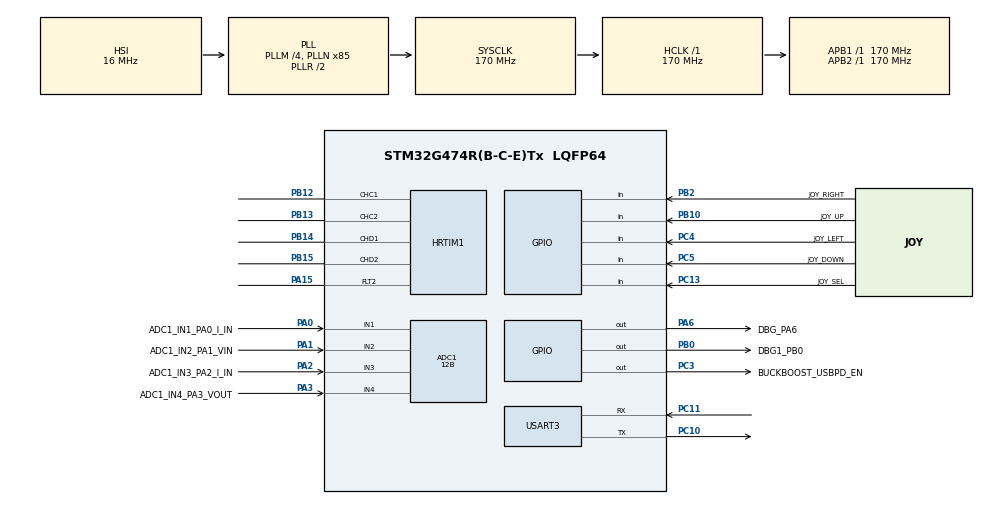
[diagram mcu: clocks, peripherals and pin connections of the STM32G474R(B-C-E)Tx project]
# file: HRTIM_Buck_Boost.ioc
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ADC1.Channel-5\#ChannelRegularConversion=ADC_CHANNEL_2
ADC1.ClockPrescaler=ADC_CLOCK_SYNC_PCLK_DIV4
ADC1.ContinuousConvMode=DISABLE
ADC1.DMAContinuousRequests=DISABLE
ADC1.DataAlign=ADC_DATAALIGN_RIGHT
ADC1.DiscontinuousConvMode=DISABLE
ADC1.EOCSelection=ADC_EOC_SINGLE_CONV
ADC1.EnableAnalogWatchDog1=false
ADC1.EnableAnalogWatchDog2=false
ADC1.EnableAnalogWatchDog3=false
ADC1.EnableInjectedConversion=ENABLE
ADC1.EnableInjectedOversampling=DISABLE
ADC1.EnableRegularConversion=ENABLE
ADC1.ExternalTrigConv=ADC_SOFTWARE_START
ADC1.ExternalTrigConvEdge=ADC_EXTERNALTRIGCONVEDGE_NONE
ADC1.ExternalTrigInjecConv=ADC_EXTERNALTRIGINJEC_HRTIM_TRG2
ADC1.ExternalTrigInjecConvEdge=ADC_EXTERNALTRIGINJECCONV_EDGE_RISING
ADC1.GainCompensation=0
ADC1.InjNumberOfConversion=4
ADC1.InjectedChannel-2\#ChannelInjectedConversion=ADC_CHANNEL_1
ADC1.InjectedChannel-4\#ChannelInjectedConversion=ADC_CHANNEL_2
ADC1.InjectedChannel-6\#ChannelInjectedConversion=ADC_CHANNEL_3
ADC1.InjectedChannel-7\#ChannelInjectedConversion=ADC_CHANNEL_4
ADC1.InjectedConvMode=None
ADC1.InjectedOffsetNumber-2\#ChannelInjectedConversion=ADC_OFFSET_NONE
ADC1.InjectedOffsetNumber-4\#ChannelInjectedConversion=ADC_OFFSET_NONE
ADC1.InjectedOffsetNumber-6\#ChannelInjectedConversion=ADC_OFFSET_NONE
ADC1.InjectedOffsetNumber-7\#ChannelInjectedConversion=ADC_OFFSET_NONE
ADC1.InjectedRank-2\#ChannelInjectedConversion=1
ADC1.InjectedRank-4\#ChannelInjectedConversion=2
ADC1.InjectedRank-6\#ChannelInjectedConversion=3
ADC1.InjectedRank-7\#ChannelInjectedConversion=4
ADC1.InjectedSamplingTime-2\#ChannelInjectedConversion=ADC_SAMPLETIME_247CYCLES_5
ADC1.InjectedSamplingTime-4\#ChannelInjectedConversion=ADC_SAMPLETIME_247CYCLES_5
ADC1.InjectedSamplingTime-6\#ChannelInjectedConversion=ADC_SAMPLETIME_247CYCLES_5
ADC1.InjectedSamplingTime-7\#ChannelInjectedConversion=ADC_SAMPLETIME_247CYCLES_5
ADC1.LowPowerAutoWait=DISABLE
ADC1.Mode=ADC_MODE_INDEPENDENT
ADC1.NbrOfConversion=1
ADC1.OffsetNumber-5\#ChannelRegularConversion=ADC_OFFSET_NONE
ADC1.Overrun=ADC_OVR_DATA_PRESERVED
ADC1.OversamplingMode=DISABLE
ADC1.Rank-5\#ChannelRegularConversion=1
ADC1.Rank1_Channel=ADC_CHANNEL_1
ADC1.Rank2_Channel=ADC_CHANNEL_2
ADC1.Rank3_Channel=ADC_CHANNEL_3
ADC1.Rank4_Channel=ADC_CHANNEL_4
ADC1.Resolution=ADC_RESOLUTION_12B
ADC1.SamplingTime-5\#ChannelRegularConversion=ADC_SAMPLETIME_247CYCLES_5
ADC1.ScanConvMode=ADC_SCAN_ENABLE
ADC1.injectedQueueMode=DISABLE
ADC1.master=1
HRTIM1.ADCTrigger2_Source1=HRTIM_ADCTRIGGEREVENT24_TIMERC_CMP2
HRTIM1.ADCTrigger_Id1=__NULL
HRTIM1.ADCTrigger_Id10=__NULL
HRTIM1.ADCTrigger_Id2=HRTIM_ADCTRIGGER_2
HRTIM1.ADCTrigger_Id3=__NULL
HRTIM1.ADCTrigger_Id4=__NULL
HRTIM1.ADCTrigger_Id5=__NULL
HRTIM1.ADCTrigger_Id6=__NULL
HRTIM1.ADCTrigger_Id7=__NULL
HRTIM1.ADCTrigger_Id8=__NULL
HRTIM1.ADCTrigger_Id9=__NULL
HRTIM1.AutoDelayedMode2-Output_TC1TC2=HRTIM_AUTODELAYEDMODE_REGULAR
HRTIM1.BlankingSourceFaultLine2=HRTIM_FAULTBLANKINGMODE_RSTALIGNED
HRTIM1.BurstDMAconfig-Output_TC1TC2=__NULL
HRTIM1.BurstDMAconfig-Output_TD1TD2=__NULL
HRTIM1.BurstMode-Output_TC1TC2=HRTIM_TIMERBURSTMODE_MAINTAINCLOCK
HRTIM1.BurstMode-Output_TD1TD2=HRTIM_TIMERBURSTMODE_MAINTAINCLOCK
HRTIM1.BurstModeEntryDelayed1-Output_TC1TC2=HRTIM_OUTPUTBURSTMODEENTRY_REGULAR
HRTIM1.BurstModeEntryDelayed1-Output_TD1TD2=HRTIM_OUTPUTBURSTMODEENTRY_REGULAR
HRTIM1.BurstModeEntryDelayed2-Output_TC1TC2=HRTIM_OUTPUTBURSTMODEENTRY_REGULAR
HRTIM1.BurstModeEntryDelayed2-Output_TD1TD2=HRTIM_OUTPUTBURSTMODEENTRY_REGULAR
HRTIM1.CaptureUnit1-Output_TC1TC2=__NULL
HRTIM1.CaptureUnit1-Output_TD1TD2=__NULL
HRTIM1.CaptureUnit2-Output_TC1TC2=__NULL
HRTIM1.CaptureUnit2-Output_TD1TD2=__NULL
HRTIM1.ChopperModeEnable1-Output_TC1TC2=HRTIM_OUTPUTCHOPPERMODE_DISABLED
HRTIM1.ChopperModeEnable1-Output_TD1TD2=HRTIM_OUTPUTCHOPPERMODE_DISABLED
HRTIM1.ChopperModeEnable2-Output_TC1TC2=HRTIM_OUTPUTCHOPPERMODE_DISABLED
HRTIM1.ChopperModeEnable2-Output_TD1TD2=HRTIM_OUTPUTCHOPPERMODE_DISABLED
HRTIM1.ChopperModeconfig-Output_TC1TC2=__NULL
HRTIM1.ChopperModeconfig-Output_TD1TD2=__NULL
HRTIM1.CompareUnit1-Output_TC1TC2=HRTIM_COMPAREUNIT_1
HRTIM1.CompareUnit1-Output_TD1TD2=HRTIM_COMPAREUNIT_1
HRTIM1.CompareUnit2-Output_TC1TC2=HRTIM_COMPAREUNIT_2
HRTIM1.CompareUnit2-Output_TD1TD2=__NULL
HRTIM1.CompareUnit3-Output_TC1TC2=__NULL
HRTIM1.CompareUnit3-Output_TD1TD2=__NULL
HRTIM1.CompareUnit4-Output_TC1TC2=__NULL
HRTIM1.CompareUnit4-Output_TD1TD2=__NULL
HRTIM1.CompareValue1-Output_TC1TC2=BUCK_PWM_PERIOD - 0x60
HRTIM1.CompareValue1-Output_TD1TD2=BUCK_PWM_PERIOD+1
HRTIM1.CompareValue2-Output_TC1TC2=BUCK_PWM_PERIOD/2
HRTIM1.Configuration_TC=Waveform
HRTIM1.Configuration_TD=Waveform
HRTIM1.CounterFaultLine2=0
HRTIM1.DACSynchro-Output_TC1TC2=HRTIM_DACSYNC_NONE
HRTIM1.DACSynchro-Output_TD1TD2=HRTIM_DACSYNC_NONE
HRTIM1.DeadTimeInsertion-Output_TC1TC2=HRTIM_TIMDEADTIMEINSERTION_ENABLED
HRTIM1.DeadTimeInsertion-Output_TD1TD2=HRTIM_TIMDEADTIMEINSERTION_ENABLED
HRTIM1.Deadtimeconfig-Output_TC1TC2=HRTIM_TIMERINDEX_TIMER_C
HRTIM1.Deadtimeconfig-Output_TD1TD2=HRTIM_TIMERINDEX_TIMER_D
HRTIM1.DelayedProtectionMode-Output_TC1TC2=HRTIM_TIMER_A_B_C_DELAYEDPROTECTION_DISABLED
HRTIM1.DelayedProtectionMode-Output_TD1TD2=HRTIM_TIMER_D_E_DELAYEDPROTECTION_DISABLED
HRTIM1.DualChannelDacEnableFake_TC-Output_TC1TC2=HRTIM_TIMER_DCDE_DISABLED
HRTIM1.DualChannelDacEnableFake_TD-Output_TD1TD2=HRTIM_TIMER_DCDE_DISABLED
HRTIM1.Enable=HRTIM_BURSTMODECTL_DISABLED
HRTIM1.Enable_FaultLine2=HRTIM_FAULTMODECTL_ENABLED
HRTIM1.Event1-Output_TC1TC2=__NULL
HRTIM1.Event1-Output_TD1TD2=__NULL
HRTIM1.Event10-Output_TC1TC2=__NULL
HRTIM1.Event10-Output_TD1TD2=__NULL
HRTIM1.Event2-Output_TC1TC2=__NULL
HRTIM1.Event2-Output_TD1TD2=__NULL
HRTIM1.Event3-Output_TC1TC2=__NULL
HRTIM1.Event3-Output_TD1TD2=__NULL
HRTIM1.Event4-Output_TC1TC2=__NULL
HRTIM1.Event4-Output_TD1TD2=__NULL
HRTIM1.Event5-Output_TC1TC2=__NULL
HRTIM1.Event5-Output_TD1TD2=__NULL
HRTIM1.Event6-Output_TC1TC2=__NULL
HRTIM1.Event6-Output_TD1TD2=__NULL
HRTIM1.Event7-Output_TC1TC2=__NULL
HRTIM1.Event7-Output_TD1TD2=__NULL
HRTIM1.Event8-Output_TC1TC2=__NULL
HRTIM1.Event8-Output_TD1TD2=__NULL
HRTIM1.Event9-Output_TC1TC2=__NULL
HRTIM1.Event9-Output_TD1TD2=__NULL
HRTIM1.EventEnableA-Output_TC1TC2=__NULL
HRTIM1.EventEnableA-Output_TD1TD2=__NULL
HRTIM1.Event_EEV1=__NULL
HRTIM1.Event_EEV10=__NULL
HRTIM1.Event_EEV2=__NULL
HRTIM1.Event_EEV3=__NULL
HRTIM1.Event_EEV4=__NULL
HRTIM1.Event_EEV5=__NULL
HRTIM1.Event_EEV6=__NULL
HRTIM1.Event_EEV7=__NULL
HRTIM1.Event_EEV8=__NULL
HRTIM1.Event_EEV9=__NULL
HRTIM1.FallingLock-Output_TC1TC2=HRTIM_TIMDEADTIME_FALLINGLOCK_WRITE
HRTIM1.FallingLock-Output_TD1TD2=HRTIM_TIMDEADTIME_FALLINGLOCK_WRITE
HRTIM1.FallingSign-Output_TC1TC2=HRTIM_TIMDEADTIME_FALLINGSIGN_POSITIVE
HRTIM1.FallingSign-Output_TD1TD2=HRTIM_TIMDEADTIME_FALLINGSIGN_POSITIVE
HRTIM1.FallingSignLock-Output_TC1TC2=HRTIM_TIMDEADTIME_FALLINGSIGNLOCK_READONLY
HRTIM1.FallingSignLock-Output_TD1TD2=HRTIM_TIMDEADTIME_FALLINGSIGNLOCK_READONLY
HRTIM1.FallingValue-Output_TC1TC2=DT_FALLING
HRTIM1.FallingValue-Output_TD1TD2=DT_FALLING
HRTIM1.FaultEnable_Source1-Output_TC1TC2=HRTIM_TIMFAULTENABLE_FAULT2
HRTIM1.FaultEnable_Source1-Output_TD1TD2=HRTIM_TIMFAULTENABLE_FAULT2
HRTIM1.FaultLevel1-Output_TC1TC2=HRTIM_OUTPUTFAULTLEVEL_INACTIVE
HRTIM1.FaultLevel1-Output_TD1TD2=HRTIM_OUTPUTFAULTLEVEL_INACTIVE
HRTIM1.FaultLevel2-Output_TC1TC2=HRTIM_OUTPUTFAULTLEVEL_INACTIVE
HRTIM1.FaultLevel2-Output_TD1TD2=HRTIM_OUTPUTFAULTLEVEL_INACTIVE
HRTIM1.FaultLock-Output_TC1TC2=HRTIM_TIMFAULTLOCK_READWRITE
HRTIM1.FaultLock-Output_TD1TD2=HRTIM_TIMFAULTLOCK_READWRITE
HRTIM1.Fault_Line1=__NULL
HRTIM1.Fault_Line2=HRTIM_FAULT_2
HRTIM1.Fault_Line3=__NULL
HRTIM1.Fault_Line4=__NULL
HRTIM1.Fault_Line5=__NULL
HRTIM1.Fault_Line6=__NULL
HRTIM1.Filter_FaultLine2=HRTIM_FAULTFILTER_NONE
HRTIM1.GreaterCMP1_TC=HRTIM_TIMERGTCMP1_EQUAL
HRTIM1.GreaterCMP1_TD=HRTIM_TIMERGTCMP1_EQUAL
HRTIM1.HRTIMInterruptResquests1=HRTIM_IT_NONE
HRTIM1.HRTIMInterruptResquests2=HRTIM_IT_NONE
HRTIM1.HRTIMInterruptResquests3=HRTIM_IT_NONE
HRTIM1.HRTIMInterruptResquests4=HRTIM_IT_NONE
HRTIM1.HRTIMInterruptResquests5=HRTIM_IT_NONE
HRTIM1.HRTIMInterruptResquests6=HRTIM_IT_NONE
HRTIM1.HRTIMInterruptResquests7=HRTIM_IT_NONE
HRTIM1.HRTIMInterruptResquests8=HRTIM_IT_NONE
HRTIM1.HRTIMInterruptResquests9=HRTIM_IT_NONE
HRTIM1.IdleLevel1-Output_TC1TC2=HRTIM_OUTPUTIDLELEVEL_INACTIVE
HRTIM1.IdleLevel1-Output_TD1TD2=HRTIM_OUTPUTIDLELEVEL_INACTIVE
HRTIM1.IdleLevel2-Output_TC1TC2=HRTIM_OUTPUTIDLELEVEL_INACTIVE
HRTIM1.IdleLevel2-Output_TD1TD2=HRTIM_OUTPUTIDLELEVEL_INACTIVE
HRTIM1.IdleMode1-Output_TC1TC2=HRTIM_OUTPUTIDLEMODE_NONE
HRTIM1.IdleMode1-Output_TD1TD2=HRTIM_OUTPUTIDLEMODE_NONE
HRTIM1.IdleMode2-Output_TC1TC2=HRTIM_OUTPUTIDLEMODE_NONE
HRTIM1.IdleMode2-Output_TD1TD2=HRTIM_OUTPUTIDLEMODE_NONE
HRTIM1.InterleavedMode-Output_TC1TC2=HRTIM_INTERLEAVED_MODE_DISABLED
HRTIM1.InterleavedMode-Output_TD1TD2=HRTIM_INTERLEAVED_MODE_DISABLED
HRTIM1.InterruptRequests1-Output_TC1TC2=HRTIM_TIM_IT_REP
HRTIM1.InterruptRequests1-Output_TD1TD2=HRTIM_TIM_IT_REP
HRTIM1.Lock_FaultLine2=HRTIM_FAULTLOCK_READWRITE
HRTIM1.ModeTimeBase-Output_TC1TC2=HRTIM_MODE_CONTINUOUS
HRTIM1.ModeTimeBase-Output_TD1TD2=HRTIM_MODE_CONTINUOUS
HRTIM1.NumberADCTriggerSource2=1
HRTIM1.NumberDMARequests_TC=0
HRTIM1.NumberDMARequests_TD=0
HRTIM1.NumberFaultEnable-Output_TC1TC2=1
HRTIM1.NumberFaultEnable-Output_TD1TD2=1
HRTIM1.NumberInterruptRequests-Output_TC1TC2=1
HRTIM1.NumberInterruptRequests-Output_TD1TD2=1
HRTIM1.NumberResetSource1-Output_TC1TC2=1
HRTIM1.NumberResetSource1-Output_TD1TD2=1
HRTIM1.NumberResetSource2_TC=1
HRTIM1.NumberResetSource2_TD=1
HRTIM1.NumberResetTrigger-Output_TC1TC2=0
HRTIM1.NumberResetTrigger-Output_TD1TD2=0
HRTIM1.NumberSetSource1-Output_TC1TC2=1
HRTIM1.NumberSetSource1-Output_TD1TD2=1
HRTIM1.NumberSetSource2_TC=1
HRTIM1.NumberSetSource2_TD=1
HRTIM1.NumberUpdateTrigger-Output_TC1TC2=0
HRTIM1.NumberUpdateTrigger-Output_TD1TD2=0
HRTIM1.ORingUpdateSource_ADCTrigger2=HRTIM_ADCTRIGGERUPDATE_TIMER_C
HRTIM1.Output1-Output_TC1TC2=HRTIM_OUTPUT_TC1
HRTIM1.Output1-Output_TD1TD2=HRTIM_OUTPUT_TD1
HRTIM1.Output2-Output_TC1TC2=HRTIM_OUTPUT_TC2
HRTIM1.Output2-Output_TD1TD2=HRTIM_OUTPUT_TD2
HRTIM1.Periode_TC=BUCK_PWM_PERIOD
HRTIM1.Periode_TD=BUCK_PWM_PERIOD
HRTIM1.Polarity1-Output_TC1TC2=HRTIM_OUTPUTPOLARITY_HIGH
HRTIM1.Polarity1-Output_TD1TD2=HRTIM_OUTPUTPOLARITY_HIGH
HRTIM1.Polarity2-Output_TC1TC2=HRTIM_OUTPUTPOLARITY_HIGH
HRTIM1.Polarity2-Output_TD1TD2=HRTIM_OUTPUTPOLARITY_HIGH
HRTIM1.Polarity_FaultLine2=HRTIM_FAULTPOLARITY_LOW
HRTIM1.PreloadEnable-Output_TC1TC2=HRTIM_PRELOAD_ENABLED
HRTIM1.PreloadEnable-Output_TD1TD2=HRTIM_PRELOAD_ENABLED
HRTIM1.PrescalerDead-Output_TC1TC2=HRTIM_TIMDEADTIME_PRESCALERRATIO_MUL8
HRTIM1.PrescalerDead-Output_TD1TD2=HRTIM_TIMDEADTIME_PRESCALERRATIO_MUL8
HRTIM1.PrescalerFault=HRTIM_FAULTPRESCALER_DIV1
HRTIM1.PushPull-Output_TC1TC2=HRTIM_TIMPUSHPULLMODE_DISABLED
HRTIM1.PushPull-Output_TD1TD2=HRTIM_TIMPUSHPULLMODE_DISABLED
HRTIM1.ReSyncUpdate-Output_TC1TC2=HRTIM_TIMERESYNC_UPDATE_UNCONDITIONAL
HRTIM1.ReSyncUpdate-Output_TD1TD2=HRTIM_TIMERESYNC_UPDATE_UNCONDITIONAL
HRTIM1.RepetitionCounter-Output_TC1TC2=31
HRTIM1.RepetitionCounter-Output_TD1TD2=31
HRTIM1.RepetitionUpdate-Output_TC1TC2=HRTIM_UPDATEONREPETITION_ENABLED
HRTIM1.RepetitionUpdate-Output_TD1TD2=HRTIM_UPDATEONREPETITION_ENABLED
HRTIM1.ResetModeFaultLine2=HRTIM_FAULTCOUNTERRST_UNCONDITIONAL
HRTIM1.ResetOnSync-Output_TC1TC2=HRTIM_SYNCRESET_DISABLED
HRTIM1.ResetOnSync-Output_TD1TD2=HRTIM_SYNCRESET_DISABLED
HRTIM1.ResetOutput1_Source1-Output_TC1TC2=HRTIM_OUTPUTRESET_TIMPER
HRTIM1.ResetOutput1_Source1-Output_TD1TD2=HRTIM_OUTPUTRESET_TIMPER
HRTIM1.ResetOutput2_Source1-Output_TC1TC2=HRTIM_OUTPUTRESET_TIMPER
HRTIM1.ResetOutput2_Source1-Output_TD1TD2=HRTIM_OUTPUTRESET_TIMPER
HRTIM1.ResetUpdate-Output_TC1TC2=HRTIM_TIMUPDATEONRESET_DISABLED
HRTIM1.ResetUpdate-Output_TD1TD2=HRTIM_TIMUPDATEONRESET_DISABLED
HRTIM1.RisingLock-Output_TC1TC2=HRTIM_TIMDEADTIME_RISINGLOCK_WRITE
HRTIM1.RisingLock-Output_TD1TD2=HRTIM_TIMDEADTIME_RISINGLOCK_WRITE
HRTIM1.RisingSign-Output_TC1TC2=HRTIM_TIMDEADTIME_RISINGSIGN_POSITIVE
HRTIM1.RisingSign-Output_TD1TD2=HRTIM_TIMDEADTIME_RISINGSIGN_POSITIVE
HRTIM1.RisingSignLock-Output_TC1TC2=HRTIM_TIMDEADTIME_RISINGSIGNLOCK_READONLY
HRTIM1.RisingSignLock-Output_TD1TD2=HRTIM_TIMDEADTIME_RISINGSIGNLOCK_READONLY
HRTIM1.RisingValue-Output_TC1TC2=DT_RISING
HRTIM1.RisingValue-Output_TD1TD2=DT_RISING
HRTIM1.SetOutput1_Source1-Output_TC1TC2=HRTIM_OUTPUTSET_TIMCMP1
HRTIM1.SetOutput1_Source1-Output_TD1TD2=HRTIM_OUTPUTSET_TIMCMP1
HRTIM1.SetOutput2_Source1-Output_TC1TC2=HRTIM_OUTPUTSET_TIMCMP1
HRTIM1.SetOutput2_Source1-Output_TD1TD2=HRTIM_OUTPUTSET_TIMCMP1
HRTIM1.Source_FaultLine2=HRTIM_FAULTSOURCE_DIGITALINPUT
HRTIM1.StartOnSync-Output_TC1TC2=HRTIM_SYNCSTART_DISABLED
HRTIM1.StartOnSync-Output_TD1TD2=HRTIM_SYNCSTART_DISABLED
HRTIM1.SwapC=__NULL
HRTIM1.SwapD=__NULL
HRTIM1.SyncOptions=HRTIM_SYNCOPTION_NONE
HRTIM1.Timeout=100
HRTIM1.TimerIdx-Output_TC1TC2=HRTIM_TIMERINDEX_TIMER_C
HRTIM1.TimerIdx-Output_TD1TD2=HRTIM_TIMERINDEX_TIMER_D
HRTIM1.TrigHalf_TC=HRTIM_TIMERTRIGHALF_DISABLED
HRTIM1.UpDownMode-Output_TC1TC2=HRTIM_TIMERUPDOWNMODE_UP
HRTIM1.UpDownMode-Output_TD1TD2=HRTIM_TIMERUPDOWNMODE_UP
HRTIM1.UpdateGating-Output_TC1TC2=HRTIM_UPDATEGATING_INDEPENDENT
HRTIM1.UpdateGating-Output_TD1TD2=HRTIM_UPDATEGATING_INDEPENDENT
HRTIM1.postscaler2=0x0
Mcu.Family=STM32G4
Mcu.Name=STM32G474R(B-C-E)Tx
Mcu.Package=LQFP64
NVIC.PriorityGroup=NVIC_PRIORITYGROUP_4
PA0.GPIO_Label=ADC1_IN1_PA0_I_IN
PA0.Signal=SharedAnalog_PA0
PA1.GPIO_Label=ADC1_IN2_PA1_VIN
PA1.Mode=IN2-Single-Ended
PA1.Signal=ADC1_IN2
PA13.GPIO_Label=T_SWDIO
PA13.Mode=Serial_Wire
PA13.Signal=SYS_JTMS-SWDIO
PA14.GPIO_Label=T_SWCLK
PA14.Mode=Serial_Wire
PA14.Signal=SYS_JTCK-SWCLK
PA15.GPIO_PuPd=GPIO_PULLUP
PA15.Mode=Fault_Enable2
PA15.Signal=HRTIM1_FLT2
PA2.GPIO_Label=ADC1_IN3_PA2_I_IN
PA2.Mode=IN3-Single-Ended
PA2.Signal=ADC1_IN3
PA3.GPIO_Label=ADC1_IN4_PA3_VOUT
PA3.Mode=IN4-Single-Ended
PA3.Signal=ADC1_IN4
PA6.GPIO_Label=DBG_PA6
PA6.Signal=GPIO_Output
PB0.GPIO_Label=DBG1_PB0
PB0.Signal=GPIO_Output
PB10.GPIO_Label=JOY_UP
PB10.GPIO_PuPd=GPIO_PULLUP
PB10.Signal=GPIO_Input
PB12.Mode=Output_TC1TC2
PB12.Signal=HRTIM1_CHC1
PB13.Mode=Output_TC1TC2
PB13.Signal=HRTIM1_CHC2
PB14.Mode=Output_TD1TD2
PB14.Signal=HRTIM1_CHD1
PB15.Mode=Output_TD1TD2
PB15.Signal=HRTIM1_CHD2
PB2.GPIO_Label=JOY_RIGHT
PB2.GPIO_PuPd=GPIO_PULLUP
PB2.Signal=GPIO_Input
PB3.GPIO_Label=T_SWO
PB3.Signal=SYS_JTDO-SWO
PC10.Mode=Asynchronous
PC10.Signal=USART3_TX
PC11.Mode=Asynchronous
PC11.Signal=USART3_RX
PC13.GPIO_Label=JOY_SEL
PC13.GPIO_PuPd=GPIO_PULLUP
PC13.Signal=GPIO_Input
PC3.GPIO_Label=BUCKBOOST_USBPD_EN
PC3.Signal=GPIO_Output
PC4.GPIO_Label=JOY_LEFT
PC4.GPIO_PuPd=GPIO_PULLUP
PC4.Signal=GPIO_Input
PC5.GPIO_Label=JOY_DOWN
PC5.GPIO_PuPd=GPIO_PULLUP
PC5.Signal=GPIO_Input
ProjectManager.HeapSize=0x200
ProjectManager.StackSize=0x400
ProjectManager.TargetToolchain=STM32CubeIDE
RCC.ADC12Freq_Value=170000000
RCC.ADC345Freq_Value=170000000
RCC.AHBFreq_Value=170000000
RCC.APB1Freq_Value=170000000
RCC.APB1TimFreq_Value=170000000
RCC.APB2Freq_Value=170000000
RCC.APB2TimFreq_Value=170000000
RCC.CortexFreq_Value=170000000
RCC.EXTERNAL_CLOCK_VALUE=12288000
RCC.HCLKFreq_Value=170000000
RCC.HSE_VALUE=24000000
RCC.HSI48_VALUE=48000000
RCC.HSI_VALUE=16000000
RCC.LSE_VALUE=32768
RCC.PLLM=RCC_PLLM_DIV4
RCC.PLLN=85
RCC.SYSCLKFreq_VALUE=170000000
RCC.SYSCLKSource=RCC_SYSCLKSOURCE_PLLCLK
RCC.USBFreq_Value=170000000
RCC.VCOOutputFreq_Value=340000000
SH.SharedAnalog_PA0.0=ADC2_IN1
SH.SharedAnalog_PA0.1=ADC1_IN1,IN1-Single-Ended
USART3.VirtualMode-Asynchronous=VM_ASYNC
VP_SYS_VS_DBSignals.Mode=DisableDeadBatterySignals
board=B-G474E-DPOW1

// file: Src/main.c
/* USER CODE BEGIN Header */
/**
  ******************************************************************************
  * @file           : main.c
  * @brief          : Main program body
  ******************************************************************************
  * @attention
  *
  * Copyright (c) 2019-2021 STMicroelectronics.
  * All rights reserved.
  *
  * This software is licensed under terms that can be found in the LICENSE file
  * in the root directory of this software component.
  * If no LICENSE file comes with this software, it is provided AS-IS.
  *
  ******************************************************************************
  */
/* USER CODE END Header */
#include "main.h"

/* USER CODE BEGIN Includes */
#include "b_g474e_dpow1.h"
#include "app.h"
#include "retarget.h"
/* USER CODE END Includes */

ADC_HandleTypeDef hadc1;

HRTIM_HandleTypeDef hhrtim1;

UART_HandleTypeDef huart3;

/* USER CODE BEGIN PV */
/* Private variables ---------------------------------------------------------*/

/* BUCK cannot re-start until Vout capacitor is de-energized below this value */
#define DE_ENERGIZING_THRESHOLD         ((uint16_t)2500)

/* BOOST cannot be started if VIN value is above this threshold */
#define OVER_VOLTAGE_PROTECTION         ((uint16_t)5000)

/* This is the VDDA supply in mV */
#define VDDA                            ((uint16_t)3300)

/* Deadtime values for buck and boost stages */
#define DT_RISING       ((uint16_t)250) // 184ns
#define DT_FALLING      ((uint16_t)300) // 220ns

__IO uint32_t Vin, Vout; /* volatile is here for debug convenience */

DemoState_TypeDef DemoState;

/* USER CODE END PV */

void SystemClock_Config(void);
static void MX_GPIO_Init(void);
static void MX_HRTIM1_Init(void);
static void MX_ADC1_Init(void);
static void MX_USART3_UART_Init(void);

int main(void)
{

  /* MCU Configuration--------------------------------------------------------*/

  /* Reset of all peripherals, Initializes the Flash interface and the Systick. */
  HAL_Init();

  /* Configure the system clock */
  SystemClock_Config();

  /* Initialize all configured peripherals */
  MX_GPIO_Init();
  MX_HRTIM1_Init();
  MX_ADC1_Init();
  MX_USART3_UART_Init();
  /* USER CODE BEGIN 2 */
  RetargetInit(&huart3);    // if you move printf retargeting into retarget.c
  APP_Init();
  /* USER CODE END 2 */

  /* Infinite loop */
  /* USER CODE BEGIN WHILE */
  while (1)
  {
	  APP_Task();
    /* USER CODE END WHILE */

  }
}

void SystemClock_Config(void)
{
  RCC_OscInitTypeDef RCC_OscInitStruct = {0};
  RCC_ClkInitTypeDef RCC_ClkInitStruct = {0};

  /** Configure the main internal regulator output voltage
  */
  HAL_PWREx_ControlVoltageScaling(PWR_REGULATOR_VOLTAGE_SCALE1_BOOST);

  /** Initializes the RCC Oscillators according to the specified parameters
  * in the RCC_OscInitTypeDef structure.
  */
  RCC_OscInitStruct.OscillatorType = RCC_OSCILLATORTYPE_HSI;
  RCC_OscInitStruct.HSIState = RCC_HSI_ON;
  RCC_OscInitStruct.HSICalibrationValue = RCC_HSICALIBRATION_DEFAULT;
  RCC_OscInitStruct.PLL.PLLState = RCC_PLL_ON;
  RCC_OscInitStruct.PLL.PLLSource = RCC_PLLSOURCE_HSI;
  RCC_OscInitStruct.PLL.PLLM = RCC_PLLM_DIV4;
  RCC_OscInitStruct.PLL.PLLN = 85;
  RCC_OscInitStruct.PLL.PLLP = RCC_PLLP_DIV2;
  RCC_OscInitStruct.PLL.PLLQ = RCC_PLLQ_DIV2;
  RCC_OscInitStruct.PLL.PLLR = RCC_PLLR_DIV2;
  if (HAL_RCC_OscConfig(&RCC_OscInitStruct) != HAL_OK)
  {
    Error_Handler();
  }

  /** Initializes the CPU, AHB and APB buses clocks
  */
  RCC_ClkInitStruct.ClockType = RCC_CLOCKTYPE_HCLK|RCC_CLOCKTYPE_SYSCLK
                              |RCC_CLOCKTYPE_PCLK1|RCC_CLOCKTYPE_PCLK2;
  RCC_ClkInitStruct.SYSCLKSource = RCC_SYSCLKSOURCE_PLLCLK;
  RCC_ClkInitStruct.AHBCLKDivider = RCC_SYSCLK_DIV1;
  RCC_ClkInitStruct.APB1CLKDivider = RCC_HCLK_DIV1;
  RCC_ClkInitStruct.APB2CLKDivider = RCC_HCLK_DIV1;

  if (HAL_RCC_ClockConfig(&RCC_ClkInitStruct, FLASH_LATENCY_4) != HAL_OK)
  {
    Error_Handler();
  }
}

static void MX_ADC1_Init(void)
{

  ADC_MultiModeTypeDef multimode = {0};
  ADC_InjectionConfTypeDef sConfigInjected = {0};
  ADC_ChannelConfTypeDef sConfig = {0};

  /** Common config
  */
  hadc1.Instance = ADC1;
  hadc1.Init.ClockPrescaler = ADC_CLOCK_SYNC_PCLK_DIV4;
  hadc1.Init.Resolution = ADC_RESOLUTION_12B;
  hadc1.Init.DataAlign = ADC_DATAALIGN_RIGHT;
  hadc1.Init.GainCompensation = 0;
  hadc1.Init.ScanConvMode = ADC_SCAN_ENABLE;
  hadc1.Init.EOCSelection = ADC_EOC_SINGLE_CONV;
  hadc1.Init.LowPowerAutoWait = DISABLE;
  hadc1.Init.ContinuousConvMode = DISABLE;
  hadc1.Init.NbrOfConversion = 1;
  hadc1.Init.DiscontinuousConvMode = DISABLE;
  hadc1.Init.ExternalTrigConv = ADC_SOFTWARE_START;
  hadc1.Init.ExternalTrigConvEdge = ADC_EXTERNALTRIGCONVEDGE_NONE;
  hadc1.Init.DMAContinuousRequests = DISABLE;
  hadc1.Init.Overrun = ADC_OVR_DATA_PRESERVED;
  hadc1.Init.OversamplingMode = DISABLE;
  if (HAL_ADC_Init(&hadc1) != HAL_OK)
  {
    Error_Handler();
  }

  /** Configure the ADC multi-mode
  */
  multimode.Mode = ADC_MODE_INDEPENDENT;
  if (HAL_ADCEx_MultiModeConfigChannel(&hadc1, &multimode) != HAL_OK)
  {
    Error_Handler();
  }

  /** Configure Injected Channel
  */
  sConfigInjected.InjectedChannel = ADC_CHANNEL_1;
  sConfigInjected.InjectedRank = ADC_INJECTED_RANK_1;
  sConfigInjected.InjectedSamplingTime = ADC_SAMPLETIME_247CYCLES_5;
  sConfigInjected.InjectedSingleDiff = ADC_SINGLE_ENDED;
  sConfigInjected.InjectedOffsetNumber = ADC_OFFSET_NONE;
  sConfigInjected.InjectedOffset = 0;
  sConfigInjected.InjectedNbrOfConversion = 4;
  sConfigInjected.InjectedDiscontinuousConvMode = DISABLE;
  sConfigInjected.AutoInjectedConv = DISABLE;
  sConfigInjected.QueueInjectedContext = DISABLE;
  sConfigInjected.ExternalTrigInjecConv = ADC_EXTERNALTRIGINJEC_HRTIM_TRG2;
  sConfigInjected.ExternalTrigInjecConvEdge = ADC_EXTERNALTRIGINJECCONV_EDGE_RISING;
  sConfigInjected.InjecOversamplingMode = DISABLE;
  if (HAL_ADCEx_InjectedConfigChannel(&hadc1, &sConfigInjected) != HAL_OK)
  {
    Error_Handler();
  }

  /** Configure Injected Channel
  */
  sConfigInjected.InjectedChannel = ADC_CHANNEL_2;
  sConfigInjected.InjectedRank = ADC_INJECTED_RANK_2;
  if (HAL_ADCEx_InjectedConfigChannel(&hadc1, &sConfigInjected) != HAL_OK)
  {
    Error_Handler();
  }

  /** Configure Injected Channel
  */
  sConfigInjected.InjectedChannel = ADC_CHANNEL_3;
  sConfigInjected.InjectedRank = ADC_INJECTED_RANK_3;
  if (HAL_ADCEx_InjectedConfigChannel(&hadc1, &sConfigInjected) != HAL_OK)
  {
    Error_Handler();
  }

  /** Configure Injected Channel
  */
  sConfigInjected.InjectedChannel = ADC_CHANNEL_4;
  sConfigInjected.InjectedRank = ADC_INJECTED_RANK_4;
  if (HAL_ADCEx_InjectedConfigChannel(&hadc1, &sConfigInjected) != HAL_OK)
  {
    Error_Handler();
  }

  /** Configure Regular Channel
  */
  sConfig.Channel = ADC_CHANNEL_2;
  sConfig.Rank = ADC_REGULAR_RANK_1;
  sConfig.SamplingTime = ADC_SAMPLETIME_247CYCLES_5;
  sConfig.SingleDiff = ADC_SINGLE_ENDED;
  sConfig.OffsetNumber = ADC_OFFSET_NONE;
  sConfig.Offset = 0;
  if (HAL_ADC_ConfigChannel(&hadc1, &sConfig) != HAL_OK)
  {
    Error_Handler();
  }

}

static void MX_HRTIM1_Init(void)
{

  HRTIM_FaultBlankingCfgTypeDef pFaultBlkCfg = {0};
  HRTIM_FaultCfgTypeDef pFaultCfg = {0};
  HRTIM_ADCTriggerCfgTypeDef pADCTriggerCfg = {0};
  HRTIM_TimeBaseCfgTypeDef pTimeBaseCfg = {0};
  HRTIM_TimerCtlTypeDef pTimerCtl = {0};
  HRTIM_TimerCfgTypeDef pTimerCfg = {0};
  HRTIM_CompareCfgTypeDef pCompareCfg = {0};
  HRTIM_DeadTimeCfgTypeDef pDeadTimeCfg = {0};
  HRTIM_OutputCfgTypeDef pOutputCfg = {0};

  hhrtim1.Instance = HRTIM1;
  hhrtim1.Init.HRTIMInterruptResquests = HRTIM_IT_NONE;
  hhrtim1.Init.SyncOptions = HRTIM_SYNCOPTION_NONE;
  if (HAL_HRTIM_Init(&hhrtim1) != HAL_OK)
  {
    Error_Handler();
  }
  if (HAL_HRTIM_DLLCalibrationStart(&hhrtim1, HRTIM_CALIBRATIONRATE_3) != HAL_OK)
  {
    Error_Handler();
  }
  if (HAL_HRTIM_PollForDLLCalibration(&hhrtim1, 100) != HAL_OK)
  {
    Error_Handler();
  }
  if (HAL_HRTIM_FaultPrescalerConfig(&hhrtim1, HRTIM_FAULTPRESCALER_DIV1) != HAL_OK)
  {
    Error_Handler();
  }
  pFaultBlkCfg.Threshold = 0;
  pFaultBlkCfg.ResetMode = HRTIM_FAULTCOUNTERRST_UNCONDITIONAL;
  pFaultBlkCfg.BlankingSource = HRTIM_FAULTBLANKINGMODE_RSTALIGNED;
  if (HAL_HRTIM_FaultCounterConfig(&hhrtim1, HRTIM_FAULT_2, &pFaultBlkCfg) != HAL_OK)
  {
    Error_Handler();
  }
  if (HAL_HRTIM_FaultBlankingConfigAndEnable(&hhrtim1, HRTIM_FAULT_2, &pFaultBlkCfg) != HAL_OK)
  {
    Error_Handler();
  }
  pFaultCfg.Source = HRTIM_FAULTSOURCE_DIGITALINPUT;
  pFaultCfg.Polarity = HRTIM_FAULTPOLARITY_LOW;
  pFaultCfg.Filter = HRTIM_FAULTFILTER_NONE;
  pFaultCfg.Lock = HRTIM_FAULTLOCK_READWRITE;
  if (HAL_HRTIM_FaultConfig(&hhrtim1, HRTIM_FAULT_2, &pFaultCfg) != HAL_OK)
  {
    Error_Handler();
  }
  HAL_HRTIM_FaultModeCtl(&hhrtim1, HRTIM_FAULT_2, HRTIM_FAULTMODECTL_ENABLED);
  pADCTriggerCfg.UpdateSource = HRTIM_ADCTRIGGERUPDATE_TIMER_C;
  pADCTriggerCfg.Trigger = HRTIM_ADCTRIGGEREVENT24_TIMERC_CMP2;
  if (HAL_HRTIM_ADCTriggerConfig(&hhrtim1, HRTIM_ADCTRIGGER_2, &pADCTriggerCfg) != HAL_OK)
  {
    Error_Handler();
  }
  if (HAL_HRTIM_ADCPostScalerConfig(&hhrtim1, HRTIM_ADCTRIGGER_2, 0x0) != HAL_OK)
  {
    Error_Handler();
  }
  pTimeBaseCfg.Period = BUCK_PWM_PERIOD;
  pTimeBaseCfg.RepetitionCounter = 31;
  pTimeBaseCfg.PrescalerRatio = HRTIM_PRESCALERRATIO_MUL32;
  pTimeBaseCfg.Mode = HRTIM_MODE_CONTINUOUS;
  if (HAL_HRTIM_TimeBaseConfig(&hhrtim1, HRTIM_TIMERINDEX_TIMER_C, &pTimeBaseCfg) != HAL_OK)
  {
    Error_Handler();
  }
  pTimerCtl.UpDownMode = HRTIM_TIMERUPDOWNMODE_UP;
  pTimerCtl.TrigHalf = HRTIM_TIMERTRIGHALF_DISABLED;
  pTimerCtl.GreaterCMP1 = HRTIM_TIMERGTCMP1_EQUAL;
  pTimerCtl.DualChannelDacEnable = HRTIM_TIMER_DCDE_DISABLED;
  if (HAL_HRTIM_WaveformTimerControl(&hhrtim1, HRTIM_TIMERINDEX_TIMER_C, &pTimerCtl) != HAL_OK)
  {
    Error_Handler();
  }
  pTimerCfg.InterruptRequests = HRTIM_TIM_IT_REP;
  pTimerCfg.DMARequests = HRTIM_TIM_DMA_NONE;
  pTimerCfg.DMASrcAddress = 0x0000;
  pTimerCfg.DMADstAddress = 0x0000;
  pTimerCfg.DMASize = 0x1;
  pTimerCfg.HalfModeEnable = HRTIM_HALFMODE_DISABLED;
  pTimerCfg.InterleavedMode = HRTIM_INTERLEAVED_MODE_DISABLED;
  pTimerCfg.StartOnSync = HRTIM_SYNCSTART_DISABLED;
  pTimerCfg.ResetOnSync = HRTIM_SYNCRESET_DISABLED;
  pTimerCfg.DACSynchro = HRTIM_DACSYNC_NONE;
  pTimerCfg.PreloadEnable = HRTIM_PRELOAD_ENABLED;
  pTimerCfg.UpdateGating = HRTIM_UPDATEGATING_INDEPENDENT;
  pTimerCfg.BurstMode = HRTIM_TIMERBURSTMODE_MAINTAINCLOCK;
  pTimerCfg.RepetitionUpdate = HRTIM_UPDATEONREPETITION_ENABLED;
  pTimerCfg.PushPull = HRTIM_TIMPUSHPULLMODE_DISABLED;
  pTimerCfg.FaultEnable = HRTIM_TIMFAULTENABLE_FAULT2;
  pTimerCfg.FaultLock = HRTIM_TIMFAULTLOCK_READWRITE;
  pTimerCfg.DeadTimeInsertion = HRTIM_TIMDEADTIMEINSERTION_ENABLED;
  pTimerCfg.DelayedProtectionMode = HRTIM_TIMER_A_B_C_DELAYEDPROTECTION_DISABLED;
  pTimerCfg.UpdateTrigger = HRTIM_TIMUPDATETRIGGER_NONE;
  pTimerCfg.ResetTrigger = HRTIM_TIMRESETTRIGGER_NONE;
  pTimerCfg.ResetUpdate = HRTIM_TIMUPDATEONRESET_DISABLED;
  pTimerCfg.ReSyncUpdate = HRTIM_TIMERESYNC_UPDATE_UNCONDITIONAL;
  if (HAL_HRTIM_WaveformTimerConfig(&hhrtim1, HRTIM_TIMERINDEX_TIMER_C, &pTimerCfg) != HAL_OK)
  {
    Error_Handler();
  }
  pTimerCfg.DelayedProtectionMode = HRTIM_TIMER_D_E_DELAYEDPROTECTION_DISABLED;
  if (HAL_HRTIM_WaveformTimerConfig(&hhrtim1, HRTIM_TIMERINDEX_TIMER_D, &pTimerCfg) != HAL_OK)
  {
    Error_Handler();
  }
  pCompareCfg.CompareValue = BUCK_PWM_PERIOD - 0x60;
  if (HAL_HRTIM_WaveformCompareConfig(&hhrtim1, HRTIM_TIMERINDEX_TIMER_C, HRTIM_COMPAREUNIT_1, &pCompareCfg) != HAL_OK)
  {
    Error_Handler();
  }
  pCompareCfg.CompareValue = BUCK_PWM_PERIOD/2;
  pCompareCfg.AutoDelayedMode = HRTIM_AUTODELAYEDMODE_REGULAR;
  pCompareCfg.AutoDelayedTimeout = 0x0000;

  if (HAL_HRTIM_WaveformCompareConfig(&hhrtim1, HRTIM_TIMERINDEX_TIMER_C, HRTIM_COMPAREUNIT_2, &pCompareCfg) != HAL_OK)
  {
    Error_Handler();
  }
  pDeadTimeCfg.Prescaler = HRTIM_TIMDEADTIME_PRESCALERRATIO_MUL8;
  pDeadTimeCfg.RisingValue = DT_RISING;
  pDeadTimeCfg.RisingSign = HRTIM_TIMDEADTIME_RISINGSIGN_POSITIVE;
  pDeadTimeCfg.RisingLock = HRTIM_TIMDEADTIME_RISINGLOCK_WRITE;
  pDeadTimeCfg.RisingSignLock = HRTIM_TIMDEADTIME_RISINGSIGNLOCK_READONLY;
  pDeadTimeCfg.FallingValue = DT_FALLING;
  pDeadTimeCfg.FallingSign = HRTIM_TIMDEADTIME_FALLINGSIGN_POSITIVE;
  pDeadTimeCfg.FallingLock = HRTIM_TIMDEADTIME_FALLINGLOCK_WRITE;
  pDeadTimeCfg.FallingSignLock = HRTIM_TIMDEADTIME_FALLINGSIGNLOCK_READONLY;
  if (HAL_HRTIM_DeadTimeConfig(&hhrtim1, HRTIM_TIMERINDEX_TIMER_C, &pDeadTimeCfg) != HAL_OK)
  {
    Error_Handler();
  }
  if (HAL_HRTIM_DeadTimeConfig(&hhrtim1, HRTIM_TIMERINDEX_TIMER_D, &pDeadTimeCfg) != HAL_OK)
  {
    Error_Handler();
  }
  pOutputCfg.Polarity = HRTIM_OUTPUTPOLARITY_HIGH;
  pOutputCfg.SetSource = HRTIM_OUTPUTSET_TIMCMP1;
  pOutputCfg.ResetSource = HRTIM_OUTPUTRESET_TIMPER;
  pOutputCfg.IdleMode = HRTIM_OUTPUTIDLEMODE_NONE;
  pOutputCfg.IdleLevel = HRTIM_OUTPUTIDLELEVEL_INACTIVE;
  pOutputCfg.FaultLevel = HRTIM_OUTPUTFAULTLEVEL_INACTIVE;
  pOutputCfg.ChopperModeEnable = HRTIM_OUTPUTCHOPPERMODE_DISABLED;
  pOutputCfg.BurstModeEntryDelayed = HRTIM_OUTPUTBURSTMODEENTRY_REGULAR;
  if (HAL_HRTIM_WaveformOutputConfig(&hhrtim1, HRTIM_TIMERINDEX_TIMER_C, HRTIM_OUTPUT_TC1, &pOutputCfg) != HAL_OK)
  {
    Error_Handler();
  }
  if (HAL_HRTIM_WaveformOutputConfig(&hhrtim1, HRTIM_TIMERINDEX_TIMER_D, HRTIM_OUTPUT_TD1, &pOutputCfg) != HAL_OK)
  {
    Error_Handler();
  }
  if (HAL_HRTIM_WaveformOutputConfig(&hhrtim1, HRTIM_TIMERINDEX_TIMER_C, HRTIM_OUTPUT_TC2, &pOutputCfg) != HAL_OK)
  {
    Error_Handler();
  }
  if (HAL_HRTIM_WaveformOutputConfig(&hhrtim1, HRTIM_TIMERINDEX_TIMER_D, HRTIM_OUTPUT_TD2, &pOutputCfg) != HAL_OK)
  {
    Error_Handler();
  }
  if (HAL_HRTIM_TimeBaseConfig(&hhrtim1, HRTIM_TIMERINDEX_TIMER_D, &pTimeBaseCfg) != HAL_OK)
  {
    Error_Handler();
  }
  if (HAL_HRTIM_WaveformTimerControl(&hhrtim1, HRTIM_TIMERINDEX_TIMER_D, &pTimerCtl) != HAL_OK)
  {
    Error_Handler();
  }
  pCompareCfg.CompareValue = BUCK_PWM_PERIOD+1;
  if (HAL_HRTIM_WaveformCompareConfig(&hhrtim1, HRTIM_TIMERINDEX_TIMER_D, HRTIM_COMPAREUNIT_1, &pCompareCfg) != HAL_OK)
  {
    Error_Handler();
  }
  HAL_HRTIM_MspPostInit(&hhrtim1);

}

static void MX_USART3_UART_Init(void)
{

  huart3.Instance = USART3;
  huart3.Init.BaudRate = 115200;
  huart3.Init.WordLength = UART_WORDLENGTH_8B;
  huart3.Init.StopBits = UART_STOPBITS_1;
  huart3.Init.Parity = UART_PARITY_NONE;
  huart3.Init.Mode = UART_MODE_TX_RX;
  huart3.Init.HwFlowCtl = UART_HWCONTROL_NONE;
  huart3.Init.OverSampling = UART_OVERSAMPLING_16;
  huart3.Init.OneBitSampling = UART_ONE_BIT_SAMPLE_DISABLE;
  huart3.Init.ClockPrescaler = UART_PRESCALER_DIV1;
  huart3.AdvancedInit.AdvFeatureInit = UART_ADVFEATURE_NO_INIT;
  if (HAL_UART_Init(&huart3) != HAL_OK)
  {
    Error_Handler();
  }
  if (HAL_UARTEx_SetTxFifoThreshold(&huart3, UART_TXFIFO_THRESHOLD_1_8) != HAL_OK)
  {
    Error_Handler();
  }
  if (HAL_UARTEx_SetRxFifoThreshold(&huart3, UART_RXFIFO_THRESHOLD_1_8) != HAL_OK)
  {
    Error_Handler();
  }
  if (HAL_UARTEx_DisableFifoMode(&huart3) != HAL_OK)
  {
    Error_Handler();
  }

}

static void MX_GPIO_Init(void)
{
  GPIO_InitTypeDef GPIO_InitStruct = {0};

  /* GPIO Ports Clock Enable */
  __HAL_RCC_GPIOC_CLK_ENABLE();
  __HAL_RCC_GPIOA_CLK_ENABLE();
  __HAL_RCC_GPIOB_CLK_ENABLE();

  /*Configure GPIO pin Output Level */
  HAL_GPIO_WritePin(BUCKBOOST_USBPD_EN_GPIO_Port, BUCKBOOST_USBPD_EN_Pin, GPIO_PIN_RESET);

  /*Configure GPIO pin Output Level */
  HAL_GPIO_WritePin(DBG_PA6_GPIO_Port, DBG_PA6_Pin, GPIO_PIN_RESET);

  /*Configure GPIO pin Output Level */
  HAL_GPIO_WritePin(DBG1_PB0_GPIO_Port, DBG1_PB0_Pin, GPIO_PIN_RESET);

  /*Configure GPIO pins : JOY_SEL_Pin JOY_LEFT_Pin JOY_DOWN_Pin */
  GPIO_InitStruct.Pin = JOY_SEL_Pin|JOY_LEFT_Pin|JOY_DOWN_Pin;
  GPIO_InitStruct.Mode = GPIO_MODE_INPUT;
  GPIO_InitStruct.Pull = GPIO_PULLUP;
  HAL_GPIO_Init(GPIOC, &GPIO_InitStruct);

  /*Configure GPIO pin : BUCKBOOST_USBPD_EN_Pin */
  GPIO_InitStruct.Pin = BUCKBOOST_USBPD_EN_Pin;
  GPIO_InitStruct.Mode = GPIO_MODE_OUTPUT_PP;
  GPIO_InitStruct.Pull = GPIO_NOPULL;
  GPIO_InitStruct.Speed = GPIO_SPEED_FREQ_LOW;
  HAL_GPIO_Init(BUCKBOOST_USBPD_EN_GPIO_Port, &GPIO_InitStruct);

  /*Configure GPIO pin : ADC1_IN1_PA0_I_IN_Pin */
  GPIO_InitStruct.Pin = ADC1_IN1_PA0_I_IN_Pin;
  GPIO_InitStruct.Mode = GPIO_MODE_ANALOG;
  GPIO_InitStruct.Pull = GPIO_NOPULL;
  HAL_GPIO_Init(ADC1_IN1_PA0_I_IN_GPIO_Port, &GPIO_InitStruct);

  /*Configure GPIO pin : DBG_PA6_Pin */
  GPIO_InitStruct.Pin = DBG_PA6_Pin;
  GPIO_InitStruct.Mode = GPIO_MODE_OUTPUT_PP;
  GPIO_InitStruct.Pull = GPIO_NOPULL;
  GPIO_InitStruct.Speed = GPIO_SPEED_FREQ_LOW;
  HAL_GPIO_Init(DBG_PA6_GPIO_Port, &GPIO_InitStruct);

  /*Configure GPIO pin : DBG1_PB0_Pin */
  GPIO_InitStruct.Pin = DBG1_PB0_Pin;
  GPIO_InitStruct.Mode = GPIO_MODE_OUTPUT_PP;
  GPIO_InitStruct.Pull = GPIO_NOPULL;
  GPIO_InitStruct.Speed = GPIO_SPEED_FREQ_LOW;
  HAL_GPIO_Init(DBG1_PB0_GPIO_Port, &GPIO_InitStruct);

  /*Configure GPIO pins : JOY_RIGHT_Pin JOY_UP_Pin */
  GPIO_InitStruct.Pin = JOY_RIGHT_Pin|JOY_UP_Pin;
  GPIO_InitStruct.Mode = GPIO_MODE_INPUT;
  GPIO_InitStruct.Pull = GPIO_PULLUP;
  HAL_GPIO_Init(GPIOB, &GPIO_InitStruct);

}

void Error_Handler(void)
{
  /* USER CODE BEGIN Error_Handler_Debug */
  /* User can add his own implementation to report the HAL error return state */

  /* Turn LED5 on */
  BSP_LED_On(LED5);
  while(1)
  {
  }
  /* USER CODE END Error_Handler_Debug */
}
